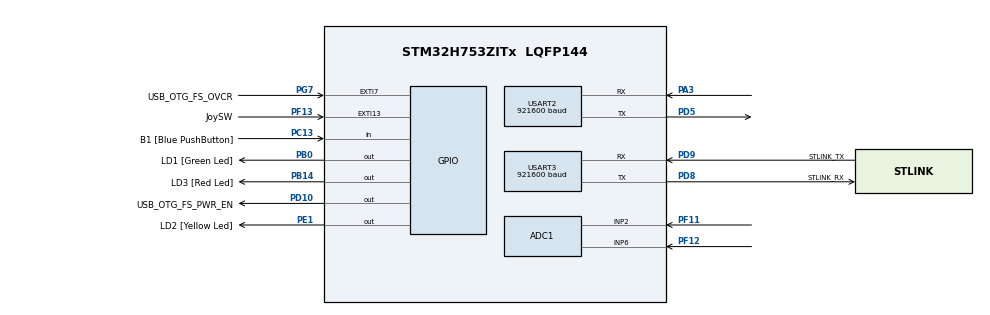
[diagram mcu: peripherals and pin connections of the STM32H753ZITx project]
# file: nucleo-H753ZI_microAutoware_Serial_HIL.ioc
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ADC1.Channel-0\#ChannelRegularConversion=ADC_CHANNEL_6
ADC1.Channel-1\#ChannelRegularConversion=ADC_CHANNEL_2
ADC1.ClockPrescaler=ADC_CLOCK_ASYNC_DIV256
ADC1.ContinuousConvMode=ENABLE
ADC1.ConversionDataManagement=ADC_CONVERSIONDATA_DMA_CIRCULAR
ADC1.NbrOfConversion=2
ADC1.NbrOfConversionFlag=1
ADC1.OffsetNumber-0\#ChannelRegularConversion=ADC_OFFSET_NONE
ADC1.OffsetNumber-1\#ChannelRegularConversion=ADC_OFFSET_NONE
ADC1.OffsetSignedSaturation-0\#ChannelRegularConversion=DISABLE
ADC1.OffsetSignedSaturation-1\#ChannelRegularConversion=DISABLE
ADC1.Rank-0\#ChannelRegularConversion=1
ADC1.Rank-1\#ChannelRegularConversion=2
ADC1.SamplingTime-0\#ChannelRegularConversion=ADC_SAMPLETIME_387CYCLES_5
ADC1.SamplingTime-1\#ChannelRegularConversion=ADC_SAMPLETIME_387CYCLES_5
ADC1.master=1
CORTEX_M7.CPU_DCache=Disabled
CORTEX_M7.CPU_ICache=Disabled
CORTEX_M7.MPU_Control=__NULL
Dma.ADC1.2.Direction=DMA_PERIPH_TO_MEMORY
Dma.ADC1.2.EventEnable=DISABLE
Dma.ADC1.2.FIFOMode=DMA_FIFOMODE_DISABLE
Dma.ADC1.2.Instance=DMA2_Stream0
Dma.ADC1.2.MemDataAlignment=DMA_MDATAALIGN_WORD
Dma.ADC1.2.MemInc=DMA_MINC_ENABLE
Dma.ADC1.2.Mode=DMA_CIRCULAR
Dma.ADC1.2.PeriphDataAlignment=DMA_PDATAALIGN_WORD
Dma.ADC1.2.PeriphInc=DMA_PINC_DISABLE
Dma.ADC1.2.Polarity=HAL_DMAMUX_REQ_GEN_RISING
Dma.ADC1.2.Priority=DMA_PRIORITY_HIGH
Dma.ADC1.2.RequestNumber=1
Dma.ADC1.2.SignalID=NONE
Dma.ADC1.2.SyncEnable=DISABLE
Dma.ADC1.2.SyncPolarity=HAL_DMAMUX_SYNC_NO_EVENT
Dma.ADC1.2.SyncRequestNumber=1
Dma.ADC1.2.SyncSignalID=NONE
Dma.Request0=USART3_RX
Dma.Request1=USART3_TX
Dma.Request2=ADC1
Dma.Request3=USART2_RX
Dma.Request4=USART2_TX
Dma.USART2_RX.3.Direction=DMA_PERIPH_TO_MEMORY
Dma.USART2_RX.3.EventEnable=DISABLE
Dma.USART2_RX.3.FIFOMode=DMA_FIFOMODE_DISABLE
Dma.USART2_RX.3.Instance=DMA2_Stream1
Dma.USART2_RX.3.MemDataAlignment=DMA_MDATAALIGN_BYTE
Dma.USART2_RX.3.MemInc=DMA_MINC_ENABLE
Dma.USART2_RX.3.Mode=DMA_NORMAL
Dma.USART2_RX.3.PeriphDataAlignment=DMA_PDATAALIGN_BYTE
Dma.USART2_RX.3.PeriphInc=DMA_PINC_DISABLE
Dma.USART2_RX.3.Polarity=HAL_DMAMUX_REQ_GEN_RISING
Dma.USART2_RX.3.Priority=DMA_PRIORITY_VERY_HIGH
Dma.USART2_RX.3.RequestNumber=1
Dma.USART2_RX.3.SignalID=NONE
Dma.USART2_RX.3.SyncEnable=DISABLE
Dma.USART2_RX.3.SyncPolarity=HAL_DMAMUX_SYNC_NO_EVENT
Dma.USART2_RX.3.SyncRequestNumber=1
Dma.USART2_RX.3.SyncSignalID=NONE
Dma.USART2_TX.4.Direction=DMA_MEMORY_TO_PERIPH
Dma.USART2_TX.4.EventEnable=DISABLE
Dma.USART2_TX.4.FIFOMode=DMA_FIFOMODE_DISABLE
Dma.USART2_TX.4.Instance=DMA2_Stream2
Dma.USART2_TX.4.MemDataAlignment=DMA_MDATAALIGN_BYTE
Dma.USART2_TX.4.MemInc=DMA_MINC_ENABLE
Dma.USART2_TX.4.Mode=DMA_NORMAL
Dma.USART2_TX.4.PeriphDataAlignment=DMA_PDATAALIGN_BYTE
Dma.USART2_TX.4.PeriphInc=DMA_PINC_DISABLE
Dma.USART2_TX.4.Polarity=HAL_DMAMUX_REQ_GEN_RISING
Dma.USART2_TX.4.Priority=DMA_PRIORITY_VERY_HIGH
Dma.USART2_TX.4.RequestNumber=1
Dma.USART2_TX.4.SignalID=NONE
Dma.USART2_TX.4.SyncEnable=DISABLE
Dma.USART2_TX.4.SyncPolarity=HAL_DMAMUX_SYNC_NO_EVENT
Dma.USART2_TX.4.SyncRequestNumber=1
Dma.USART2_TX.4.SyncSignalID=NONE
Dma.USART3_RX.0.Direction=DMA_PERIPH_TO_MEMORY
Dma.USART3_RX.0.EventEnable=DISABLE
Dma.USART3_RX.0.FIFOMode=DMA_FIFOMODE_DISABLE
Dma.USART3_RX.0.Instance=DMA1_Stream0
Dma.USART3_RX.0.MemDataAlignment=DMA_MDATAALIGN_BYTE
Dma.USART3_RX.0.MemInc=DMA_MINC_ENABLE
Dma.USART3_RX.0.Mode=DMA_CIRCULAR
Dma.USART3_RX.0.PeriphDataAlignment=DMA_PDATAALIGN_BYTE
Dma.USART3_RX.0.PeriphInc=DMA_PINC_DISABLE
Dma.USART3_RX.0.Polarity=HAL_DMAMUX_REQ_GEN_RISING
Dma.USART3_RX.0.Priority=DMA_PRIORITY_VERY_HIGH
Dma.USART3_RX.0.RequestNumber=1
Dma.USART3_RX.0.SignalID=NONE
Dma.USART3_RX.0.SyncEnable=DISABLE
Dma.USART3_RX.0.SyncPolarity=HAL_DMAMUX_SYNC_NO_EVENT
Dma.USART3_RX.0.SyncRequestNumber=1
Dma.USART3_RX.0.SyncSignalID=NONE
Dma.USART3_TX.1.Direction=DMA_MEMORY_TO_PERIPH
Dma.USART3_TX.1.EventEnable=DISABLE
Dma.USART3_TX.1.FIFOMode=DMA_FIFOMODE_DISABLE
Dma.USART3_TX.1.Instance=DMA1_Stream1
Dma.USART3_TX.1.MemDataAlignment=DMA_MDATAALIGN_BYTE
Dma.USART3_TX.1.MemInc=DMA_MINC_ENABLE
Dma.USART3_TX.1.Mode=DMA_NORMAL
Dma.USART3_TX.1.PeriphDataAlignment=DMA_PDATAALIGN_BYTE
Dma.USART3_TX.1.PeriphInc=DMA_PINC_DISABLE
Dma.USART3_TX.1.Polarity=HAL_DMAMUX_REQ_GEN_RISING
Dma.USART3_TX.1.Priority=DMA_PRIORITY_VERY_HIGH
Dma.USART3_TX.1.RequestNumber=1
Dma.USART3_TX.1.SignalID=NONE
Dma.USART3_TX.1.SyncEnable=DISABLE
Dma.USART3_TX.1.SyncPolarity=HAL_DMAMUX_SYNC_NO_EVENT
Dma.USART3_TX.1.SyncRequestNumber=1
Dma.USART3_TX.1.SyncSignalID=NONE
FREERTOS.Events01=EventsMicroAutoware,Dynamic,NULL
FREERTOS.Mutexes01=MutexVehicleStatus,Dynamic,NULL;MutexControlAction,Dynamic,NULL
FREERTOS.Tasks01=TaskControl,32,1500,StartTaskControl,As weak,NULL,Dynamic,NULL,NULL;TaskMicroAutowa,24,4500,StartMicroAutoware,As external,NULL,Dynamic,NULL,NULL
FREERTOS.configCHECK_FOR_STACK_OVERFLOW=0
FREERTOS.configENABLE_FPU=1
FREERTOS.configTOTAL_HEAP_SIZE=200000
FREERTOS.configUSE_MALLOC_FAILED_HOOK=0
FREERTOS.configUSE_NEWLIB_REENTRANT=1
Mcu.Family=STM32H7
Mcu.Name=STM32H753ZITx
Mcu.Package=LQFP144
NVIC.DMA1_Stream0_IRQn=true\:5\:0\:false\:false\:true\:true\:true\:true\:true
NVIC.DMA1_Stream1_IRQn=true\:5\:0\:false\:false\:true\:true\:true\:true\:true
NVIC.DMA2_Stream1_IRQn=true\:5\:0\:false\:false\:true\:true\:true\:true\:true
NVIC.DMA2_Stream2_IRQn=true\:5\:0\:false\:false\:true\:true\:true\:true\:true
NVIC.EXTI15_10_IRQn=true\:7\:0\:true\:false\:true\:true\:true\:true\:true
NVIC.PriorityGroup=NVIC_PRIORITYGROUP_4
NVIC.TIM6_DAC_IRQn=true\:15\:0\:false\:false\:true\:false\:false\:true\:true
NVIC.TimeBase=TIM6_DAC_IRQn
NVIC.TimeBaseIP=TIM6
NVIC.USART2_IRQn=true\:5\:0\:true\:false\:true\:true\:true\:true\:true
NVIC.USART3_IRQn=true\:8\:0\:true\:false\:true\:true\:true\:true\:true
PA1.Signal=ETH_REF_CLK
PA11.Signal=USB_OTG_FS_DM
PA12.Signal=USB_OTG_FS_DP
PA2.Signal=ETH_MDIO
PA3.Mode=Asynchronous
PA3.Signal=USART2_RX
PA7.Signal=ETH_CRS_DV
PA8.Signal=USB_OTG_FS_SOF
PA9.Signal=USB_OTG_FS_VBUS
PB0.GPIO_Label=LD1 [Green Led]
PB0.Signal=GPIO_Output
PB13.Signal=ETH_TXD1
PB14.GPIO_Label=LD3 [Red Led]
PB14.Signal=GPIO_Output
PC1.Signal=ETH_MDC
PC13.GPIO_Label=B1 [Blue PushButton]
PC13.Signal=GPIO_Input
PC14-OSC32_IN\ (OSC32_IN).Mode=LSE-External-Oscillator
PC14-OSC32_IN\ (OSC32_IN).Signal=RCC_OSC32_IN
PC15-OSC32_OUT\ (OSC32_OUT).Mode=LSE-External-Oscillator
PC15-OSC32_OUT\ (OSC32_OUT).Signal=RCC_OSC32_OUT
PC4.Signal=ETH_RXD0
PC5.Signal=ETH_RXD1
PD10.GPIO_Label=USB_OTG_FS_PWR_EN
PD10.Signal=GPIO_Output
PD5.Mode=Asynchronous
PD5.Signal=USART2_TX
PD8.GPIO_Label=STLINK_RX
PD8.Mode=Asynchronous
PD8.Signal=USART3_TX
PD9.GPIO_Label=STLINK_TX
PD9.Mode=Asynchronous
PD9.Signal=USART3_RX
PE1.GPIO_Label=LD2 [Yellow Led]
PE1.Signal=GPIO_Output
PF11.Mode=IN2-Single-Ended
PF11.Signal=ADC1_INP2
PF12.Mode=IN6-Single-Ended
PF12.Signal=ADC1_INP6
PF13.GPIO_Label=JoySW
PF13.GPIO_PuPd=GPIO_PULLUP
PF13.Signal=GPXTI13
PG11.Signal=ETH_TX_EN
PG13.Signal=ETH_TXD0
PG7.GPIO_Label=USB_OTG_FS_OVCR
PG7.Signal=GPXTI7
PH0-OSC_IN\ (PH0).Mode=HSE-External-Clock-Source
PH0-OSC_IN\ (PH0).Signal=RCC_OSC_IN
PH1-OSC_OUT\ (PH1).Signal=RCC_OSC_OUT
ProjectManager.HeapSize=0x200
ProjectManager.StackSize=0x400
ProjectManager.TargetToolchain=STM32CubeIDE
RCC.ADCFreq_Value=75000000
RCC.APB1Freq_Value=120000000
RCC.APB2Freq_Value=120000000
RCC.APB3Freq_Value=120000000
RCC.APB4Freq_Value=120000000
RCC.CortexFreq_Value=480000000
RCC.D1PPRE=RCC_APB3_DIV2
RCC.D2PPRE1=RCC_APB1_DIV2
RCC.D2PPRE2=RCC_APB2_DIV2
RCC.D3PPRE=RCC_APB4_DIV2
RCC.DIVM1=1
RCC.DIVM2=1
RCC.DIVN1=240
RCC.DIVN2=37
RCC.DIVQ1=4
RCC.HCLKFreq_Value=240000000
RCC.HPRE=RCC_HCLK_DIV2
RCC.HSE_VALUE=8000000
RCC.PLL2FRACN=4096
RCC.PLLFRACN=0
RCC.PLLSourceVirtual=RCC_PLLSOURCE_CSI
RCC.PWR_Regulator_Voltage_Scale=PWR_REGULATOR_VOLTAGE_SCALE0
RCC.SYSCLKFreq_VALUE=480000000
RCC.SYSCLKSource=RCC_SYSCLKSOURCE_PLLCLK
RCC.USBCLockSelection=RCC_USBCLKSOURCE_HSI48
RCC.USBFreq_Value=48000000
USART2.BaudRate=921600
USART2.VirtualMode-Asynchronous=VM_ASYNC
USART3.AutoBaudRateEnableParam=UART_ADVFEATURE_AUTOBAUDRATE_DISABLE
USART3.BaudRate=921600
USART3.ClockPrescaler=PRESCALER_DIV1
USART3.DMADisableonRxErrorParam=ADVFEATURE_DMA_ENABLEONRXERROR
USART3.DataInvertParam=ADVFEATURE_DATAINV_DISABLE
USART3.FIFOMode=FIFOMODE_DISABLE
USART3.MSBFirstParam=ADVFEATURE_MSBFIRST_DISABLE
USART3.Mode=MODE_TX_RX
USART3.OneBitSampling=UART_ONE_BIT_SAMPLE_DISABLE
USART3.OverSampling=UART_OVERSAMPLING_16
USART3.OverrunDisableParam=ADVFEATURE_OVERRUN_ENABLE
USART3.Parity=PARITY_NONE
USART3.RXFIFOThreshold=RXFIFO_THRESHOLD_1EIGHTHFULL
USART3.RxPinLevelInvertParam=ADVFEATURE_RXINV_DISABLE
USART3.StopBits=STOPBITS_1
USART3.SwapParam=ADVFEATURE_SWAP_DISABLE
USART3.TXFIFOThreshold=TXFIFO_THRESHOLD_1EIGHTHFULL
USART3.TxPinLevelInvertParam=ADVFEATURE_TXINV_DISABLE
USART3.VirtualMode-Asynchronous=VM_ASYNC
USART3.WordLength=WORDLENGTH_8B
VP_FREERTOS_VS_CMSIS_V2.Mode=CMSIS_V2
VP_SYS_VS_tim6.Mode=TIM6
board=NUCLEO-H753ZI

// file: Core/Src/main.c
/* USER CODE BEGIN Header */
/**
  ******************************************************************************
  * @file           : main.c
  * @brief          : Main program body
  ******************************************************************************
  * @attention
  *
  * Copyright (c) 2024 STMicroelectronics.
  * All rights reserved.
  *
  * This software is licensed under terms that can be found in the LICENSE file
  * in the root directory of this software component.
  * If no LICENSE file comes with this software, it is provided AS-IS.
  *
  ******************************************************************************
  */
/* USER CODE END Header */
#include "main.h"
#include "cmsis_os.h"
#include "adc.h"
#include "dma.h"
#include "usart.h"
#include "gpio.h"

/* USER CODE BEGIN Includes */
#include "microAutoware.h"
/* USER CODE END Includes */

void SystemClock_Config(void);
void MX_FREERTOS_Init(void);

int main(void)
{

  /* MCU Configuration--------------------------------------------------------*/

  /* Reset of all peripherals, Initializes the Flash interface and the Systick. */
  HAL_Init();

  /* Configure the system clock */
  SystemClock_Config();

  /* Initialize all configured peripherals */
  MX_GPIO_Init();
  MX_DMA_Init();
  MX_USART3_UART_Init();
  MX_ADC1_Init();
  MX_USART2_UART_Init();

  /* Init scheduler */
  osKernelInitialize();

  /* Call init function for freertos objects (in cmsis_os2.c) */
  MX_FREERTOS_Init();

  /* Start scheduler */
  osKernelStart();

  /* We should never get here as control is now taken by the scheduler */

  /* Infinite loop */
  while (1)
  {

  }
}

void SystemClock_Config(void)
{
  RCC_OscInitTypeDef RCC_OscInitStruct = {0};
  RCC_ClkInitTypeDef RCC_ClkInitStruct = {0};

  /** Supply configuration update enable
  */
  HAL_PWREx_ConfigSupply(PWR_LDO_SUPPLY);

  /** Configure the main internal regulator output voltage
  */
  __HAL_PWR_VOLTAGESCALING_CONFIG(PWR_REGULATOR_VOLTAGE_SCALE1);

  while(!__HAL_PWR_GET_FLAG(PWR_FLAG_VOSRDY)) {}

  __HAL_RCC_SYSCFG_CLK_ENABLE();
  __HAL_PWR_VOLTAGESCALING_CONFIG(PWR_REGULATOR_VOLTAGE_SCALE0);

  while(!__HAL_PWR_GET_FLAG(PWR_FLAG_VOSRDY)) {}

  /** Initializes the RCC Oscillators according to the specified parameters
  * in the RCC_OscInitTypeDef structure.
  */
  RCC_OscInitStruct.OscillatorType = RCC_OSCILLATORTYPE_CSI;
  RCC_OscInitStruct.CSIState = RCC_CSI_ON;
  RCC_OscInitStruct.CSICalibrationValue = RCC_CSICALIBRATION_DEFAULT;
  RCC_OscInitStruct.PLL.PLLState = RCC_PLL_ON;
  RCC_OscInitStruct.PLL.PLLSource = RCC_PLLSOURCE_CSI;
  RCC_OscInitStruct.PLL.PLLM = 1;
  RCC_OscInitStruct.PLL.PLLN = 240;
  RCC_OscInitStruct.PLL.PLLP = 2;
  RCC_OscInitStruct.PLL.PLLQ = 4;
  RCC_OscInitStruct.PLL.PLLR = 2;
  RCC_OscInitStruct.PLL.PLLRGE = RCC_PLL1VCIRANGE_2;
  RCC_OscInitStruct.PLL.PLLVCOSEL = RCC_PLL1VCOWIDE;
  RCC_OscInitStruct.PLL.PLLFRACN = 0;
  if (HAL_RCC_OscConfig(&RCC_OscInitStruct) != HAL_OK)
  {
    Error_Handler();
  }

  /** Initializes the CPU, AHB and APB buses clocks
  */
  RCC_ClkInitStruct.ClockType = RCC_CLOCKTYPE_HCLK|RCC_CLOCKTYPE_SYSCLK
                              |RCC_CLOCKTYPE_PCLK1|RCC_CLOCKTYPE_PCLK2
                              |RCC_CLOCKTYPE_D3PCLK1|RCC_CLOCKTYPE_D1PCLK1;
  RCC_ClkInitStruct.SYSCLKSource = RCC_SYSCLKSOURCE_PLLCLK;
  RCC_ClkInitStruct.SYSCLKDivider = RCC_SYSCLK_DIV1;
  RCC_ClkInitStruct.AHBCLKDivider = RCC_HCLK_DIV2;
  RCC_ClkInitStruct.APB3CLKDivider = RCC_APB3_DIV2;
  RCC_ClkInitStruct.APB1CLKDivider = RCC_APB1_DIV2;
  RCC_ClkInitStruct.APB2CLKDivider = RCC_APB2_DIV2;
  RCC_ClkInitStruct.APB4CLKDivider = RCC_APB4_DIV2;

  if (HAL_RCC_ClockConfig(&RCC_ClkInitStruct, FLASH_LATENCY_4) != HAL_OK)
  {
    Error_Handler();
  }
}

void HAL_TIM_PeriodElapsedCallback(TIM_HandleTypeDef *htim)
{
  if (htim->Instance == TIM6) {
    HAL_IncTick();
  }
}

void Error_Handler(void)
{
  __disable_irq();
  while (1)
  {
  }
}

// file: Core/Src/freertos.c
/* USER CODE BEGIN Header */
/**
  ******************************************************************************
  * @file    freertos.c
  * @brief   Base code for FreeRTOS applcation. Declaration of tasks, global
  *          variables, kernel objects, typedefs and project libraries.
  ******************************************************************************
  * @author  Gabriel Toffanetto França da Rocha
  *          Laboratory of Autonomous Vehicles (LMA) - FEM/Unicamp
  * @date    Created:  October 9, 2024
  *          Modified:
  ******************************************************************************
  */
/* USER CODE END Header */

#include <taskControl.h>
#include "FreeRTOS.h"
#include "task.h"
#include "main.h"
#include "cmsis_os.h"

/* USER CODE BEGIN Includes */

// Tasks includes -- START
#include "microAutoware.h"

// Tasks includes -- END

// Libraries includes -- START
#include "light_printf.h"
#include "utils.h"

// Libraries includes -- END

/* USER CODE END Includes */

/* Definitions for TaskControl */
osThreadId_t TaskControlHandle;
const osThreadAttr_t TaskControl_attributes = {
  .name = "TaskControl",
  .stack_size = 1500 * 4,
  .priority = (osPriority_t) osPriorityAboveNormal,
};
/* Definitions for TaskMicroAutowa */
osThreadId_t TaskMicroAutowaHandle;
const osThreadAttr_t TaskMicroAutowa_attributes = {
  .name = "TaskMicroAutowa",
  .stack_size = 4500 * 4,
  .priority = (osPriority_t) osPriorityNormal,
};
/* Definitions for MutexVehicleStatus */
osMutexId_t MutexVehicleStatusHandle;
const osMutexAttr_t MutexVehicleStatus_attributes = {
  .name = "MutexVehicleStatus"
};
/* Definitions for MutexControlAction */
osMutexId_t MutexControlActionHandle;
const osMutexAttr_t MutexControlAction_attributes = {
  .name = "MutexControlAction"
};
/* Definitions for EventsMicroAutoware */
osEventFlagsId_t EventsMicroAutowareHandle;
const osEventFlagsAttr_t EventsMicroAutoware_attributes = {
  .name = "EventsMicroAutoware"
};

void StartTaskControl(void *argument);
extern void StartMicroAutoware(void *argument);

void MX_FREERTOS_Init(void); /* (MISRA C 2004 rule 8.1) */

void MX_FREERTOS_Init(void) {
  /* Create the mutex(es) */
  /* creation of MutexVehicleStatus */
  MutexVehicleStatusHandle = osMutexNew(&MutexVehicleStatus_attributes);

  /* creation of MutexControlAction */
  MutexControlActionHandle = osMutexNew(&MutexControlAction_attributes);

  /* Create the thread(s) */
  /* creation of TaskControl */
  TaskControlHandle = osThreadNew(StartTaskControl, NULL, &TaskControl_attributes);

  /* creation of TaskMicroAutowa */
  TaskMicroAutowaHandle = osThreadNew(StartMicroAutoware, NULL, &TaskMicroAutowa_attributes);

  /* creation of EventsMicroAutoware */
  EventsMicroAutowareHandle = osEventFlagsNew(&EventsMicroAutoware_attributes);

}

__weak void StartTaskControl(void *argument)
{
  for(;;)
  {
    osDelay(1);
  }
}
